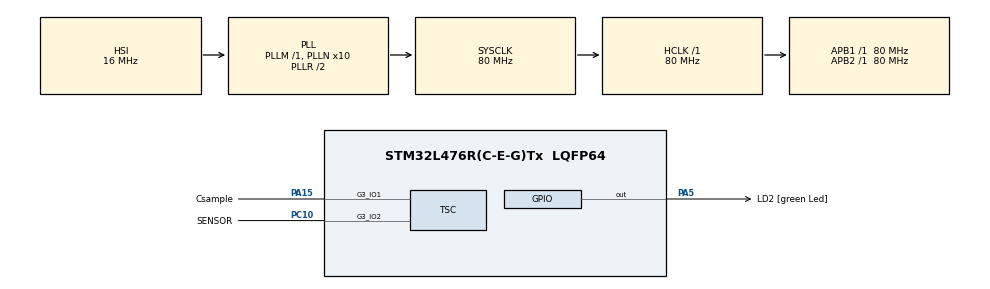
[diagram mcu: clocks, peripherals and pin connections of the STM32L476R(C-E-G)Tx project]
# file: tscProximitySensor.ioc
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Mcu.Family=STM32L4
Mcu.Name=STM32L476R(C-E-G)Tx
Mcu.Package=LQFP64
NVIC.PriorityGroup=NVIC_PRIORITYGROUP_4
PA13\ (JTMS-SWDIO).GPIO_Label=TMS
PA13\ (JTMS-SWDIO).Mode=Serial_Wire
PA13\ (JTMS-SWDIO).Signal=SYS_JTMS-SWDIO
PA14\ (JTCK-SWCLK).GPIO_Label=TCK
PA14\ (JTCK-SWCLK).Mode=Serial_Wire
PA14\ (JTCK-SWCLK).Signal=SYS_JTCK-SWCLK
PA15\ (JTDI).GPIO_Label=Csample
PA15\ (JTDI).Mode=G3_IO1-Sampling
PA15\ (JTDI).Signal=TSC_G3_IO1
PA5.GPIO_Label=LD2 [green Led]
PA5.GPIO_ModeDefaultOutputPP=GPIO_MODE_OUTPUT_PP
PA5.GPIO_PuPd=GPIO_NOPULL
PA5.GPIO_Speed=GPIO_SPEED_FREQ_LOW
PA5.Signal=GPIO_Output
PC10.GPIO_Label=SENSOR
PC10.Mode=G3_IO2-Channel
PC10.Signal=TSC_G3_IO2
ProjectManager.HeapSize=0x200
ProjectManager.StackSize=0x400
ProjectManager.TargetToolchain=STM32CubeIDE
RCC.ADCFreq_Value=64000000
RCC.AHBFreq_Value=80000000
RCC.APB1Freq_Value=80000000
RCC.APB1TimFreq_Value=80000000
RCC.APB2Freq_Value=80000000
RCC.APB2TimFreq_Value=80000000
RCC.CortexFreq_Value=80000000
RCC.HCLKFreq_Value=80000000
RCC.HSE_VALUE=8000000
RCC.HSICalibrationValue=31
RCC.HSI_VALUE=16000000
RCC.LSE_VALUE=32768
RCC.MSI_VALUE=4000000
RCC.PLLN=10
RCC.PLLSourceVirtual=RCC_PLLSOURCE_HSI
RCC.PREFETCH_ENABLE=1
RCC.SYSCLKFreq_VALUE=80000000
RCC.SYSCLKSource=RCC_SYSCLKSOURCE_PLLCLK
RCC.USBFreq_Value=64000000
RCC.VCOOutputFreq_Value=160000000
TSC.CTPulseHighLength=TSC_CTPH_16CYCLES
TSC.CTPulseLowLength=TSC_CTPL_16CYCLES
TSC.ChannelIOs-G3_IO2-Channel=TSC_GROUP3_IO2
TSC.IODefaultMode=TSC_IODEF_IN_FLOAT
TSC.MaxCountValue=TSC_MCV_16383
TSC.PulseGeneratorPrescaler=TSC_PG_PRESC_DIV1
TSC.SamplingIOs-G3_IO1-Sampling=TSC_GROUP3_IO1
TSC.SpreadSpectrum=ENABLE
board=NUCLEO-L476RG

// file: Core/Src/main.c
/* USER CODE BEGIN Header */
/**
  ******************************************************************************
  * @file           : main.c
  * @brief          : Main program body
  ******************************************************************************
  * @attention
  *
  * <h2><center>&copy; Copyright (c) 2021 STMicroelectronics.
  * All rights reserved.</center></h2>
  *
  * This software component is licensed by ST under BSD 3-Clause license,
  * the "License"; You may not use this file except in compliance with the
  * License. You may obtain a copy of the License at:
  *                        opensource.org/licenses/BSD-3-Clause
  *
  ******************************************************************************
  */
/* USER CODE END Header */
#include "main.h"

TSC_HandleTypeDef htsc;

/* USER CODE BEGIN PV */
uint16_t OUT;
/* USER CODE END PV */

void SystemClock_Config(void);
static void MX_GPIO_Init(void);
static void MX_TSC_Init(void);

int main(void)
{

  /* MCU Configuration--------------------------------------------------------*/

  /* Reset of all peripherals, Initializes the Flash interface and the Systick. */
  HAL_Init();

  /* Configure the system clock */
  SystemClock_Config();

  /* Initialize all configured peripherals */
  MX_TSC_Init();
  MX_GPIO_Init();

  /* USER CODE BEGIN 2 */
HAL_TSC_Start(&htsc);	//correct
TSC->CR |= (1 << TSC_CR_TSCE);
  /* USER CODE END 2 */

  /* Infinite loop */
  /* USER CODE BEGIN WHILE */
HAL_TSC_IODischarge(&htsc, ENABLE);
HAL_Delay(1);
  while (1)
  {

	  TSC->CR |= (1 << TSC_CR_TSCE);
//	  while((TSC -> CR & TSC_CR_START)!=0){};	//check of ready (start bit = 0)
	  while (HAL_TSC_GetState(&htsc) == HAL_TSC_STATE_BUSY){}
	  __HAL_TSC_CLEAR_FLAG(&htsc, (TSC_FLAG_EOA | TSC_FLAG_MCE));
	  HAL_TSC_IODischarge(&htsc, ENABLE);
	  HAL_Delay(10);
	  if (HAL_TSC_GroupGetStatus(&htsc, TSC_GROUP3_IDX) == TSC_GROUP_COMPLETED){
	      OUT = HAL_TSC_GroupGetValue(&htsc, TSC_GROUP3_IDX);
	  }

    /* USER CODE END WHILE */

  }
}

void SystemClock_Config(void)
{
  RCC_OscInitTypeDef RCC_OscInitStruct = {0};
  RCC_ClkInitTypeDef RCC_ClkInitStruct = {0};

  /** Configure the main internal regulator output voltage
  */
  if (HAL_PWREx_ControlVoltageScaling(PWR_REGULATOR_VOLTAGE_SCALE1) != HAL_OK)
  {
    Error_Handler();
  }
  /** Initializes the RCC Oscillators according to the specified parameters
  * in the RCC_OscInitTypeDef structure.
  */
  RCC_OscInitStruct.OscillatorType = RCC_OSCILLATORTYPE_HSI;
  RCC_OscInitStruct.HSIState = RCC_HSI_ON;
  RCC_OscInitStruct.HSICalibrationValue = 31;
  RCC_OscInitStruct.PLL.PLLState = RCC_PLL_ON;
  RCC_OscInitStruct.PLL.PLLSource = RCC_PLLSOURCE_HSI;
  RCC_OscInitStruct.PLL.PLLM = 1;
  RCC_OscInitStruct.PLL.PLLN = 10;
  RCC_OscInitStruct.PLL.PLLP = RCC_PLLP_DIV7;
  RCC_OscInitStruct.PLL.PLLQ = RCC_PLLQ_DIV2;
  RCC_OscInitStruct.PLL.PLLR = RCC_PLLR_DIV2;
  if (HAL_RCC_OscConfig(&RCC_OscInitStruct) != HAL_OK)
  {
    Error_Handler();
  }
  /** Initializes the CPU, AHB and APB buses clocks
  */
  RCC_ClkInitStruct.ClockType = RCC_CLOCKTYPE_HCLK|RCC_CLOCKTYPE_SYSCLK
                              |RCC_CLOCKTYPE_PCLK1|RCC_CLOCKTYPE_PCLK2;
  RCC_ClkInitStruct.SYSCLKSource = RCC_SYSCLKSOURCE_PLLCLK;
  RCC_ClkInitStruct.AHBCLKDivider = RCC_SYSCLK_DIV1;
  RCC_ClkInitStruct.APB1CLKDivider = RCC_HCLK_DIV1;
  RCC_ClkInitStruct.APB2CLKDivider = RCC_HCLK_DIV1;

  if (HAL_RCC_ClockConfig(&RCC_ClkInitStruct, FLASH_LATENCY_4) != HAL_OK)
  {
    Error_Handler();
  }
}

static void MX_TSC_Init(void)
{

  /** Configure the TSC peripheral
  */
  htsc.Instance = TSC;
  htsc.Init.CTPulseHighLength = TSC_CTPH_16CYCLES;
  htsc.Init.CTPulseLowLength = TSC_CTPL_16CYCLES;
  htsc.Init.SpreadSpectrum = ENABLE;
  htsc.Init.SpreadSpectrumDeviation = 1;
  htsc.Init.SpreadSpectrumPrescaler = TSC_SS_PRESC_DIV1;
  htsc.Init.PulseGeneratorPrescaler = TSC_PG_PRESC_DIV1;
  htsc.Init.MaxCountValue = TSC_MCV_16383;
  htsc.Init.IODefaultMode = TSC_IODEF_IN_FLOAT;
  htsc.Init.SynchroPinPolarity = TSC_SYNC_POLARITY_FALLING;
  htsc.Init.AcquisitionMode = TSC_ACQ_MODE_NORMAL;
  htsc.Init.MaxCountInterrupt = DISABLE;
  htsc.Init.ChannelIOs = TSC_GROUP3_IO2;
  htsc.Init.ShieldIOs = 0;
  htsc.Init.SamplingIOs = TSC_GROUP3_IO1;
  if (HAL_TSC_Init(&htsc) != HAL_OK)
  {
    Error_Handler();
  }

}

static void MX_GPIO_Init(void)
{
  GPIO_InitTypeDef GPIO_InitStruct = {0};

  /* GPIO Ports Clock Enable */
  __HAL_RCC_GPIOA_CLK_ENABLE();
  __HAL_RCC_GPIOC_CLK_ENABLE();

  /*Configure GPIO pin Output Level */
  HAL_GPIO_WritePin(LD2_GPIO_Port, LD2_Pin, GPIO_PIN_RESET);

  /*Configure GPIO pin : LD2_Pin */
  GPIO_InitStruct.Pin = LD2_Pin;
  GPIO_InitStruct.Mode = GPIO_MODE_OUTPUT_PP;
  GPIO_InitStruct.Pull = GPIO_NOPULL;
  GPIO_InitStruct.Speed = GPIO_SPEED_FREQ_LOW;
  HAL_GPIO_Init(LD2_GPIO_Port, &GPIO_InitStruct);

}

void Error_Handler(void)
{
  __disable_irq();
  while (1)
  {
  }
}

/************************ (C) COPYRIGHT STMicroelectronics *****END OF FILE****/
